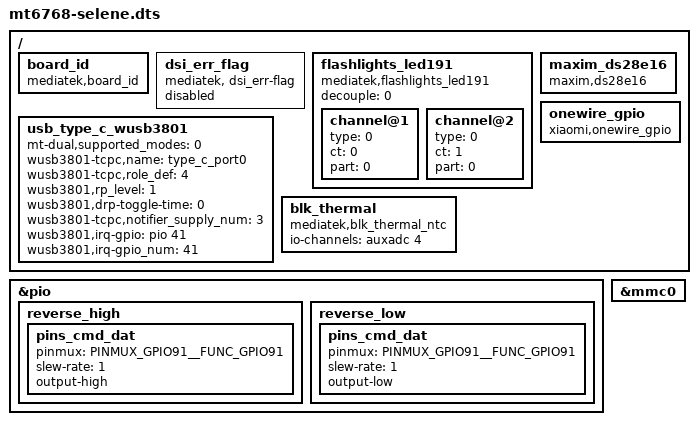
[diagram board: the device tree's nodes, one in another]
// SPDX-License-Identifier: GPL-2.0
/*
 * MT6768 base for selene (Redmi 10): the 4.19 donor base plus the
 * Xiaomi/Huaqin board nodes that selene's overlay references. Node bodies are
 * copied unchanged from the selene 4.14 mt6768.dts.
 */
#include "mt6768.dts"

/ {
    board_id: board_id {
		compatible = "mediatek,board_id";
	};

	dsi_err_flag: dsi_err_flag {
		compatible = "mediatek, dsi_err-flag";
		status = "disabled";
	};

	flashlights_led191: flashlights_led191 {
		compatible = "mediatek,flashlights_led191";
		decouple = <0>;
		channel@1 {
			type = <0>;
			ct = <0>;
			part = <0>;
		};
		channel@2 {
			type = <0>;
			ct = <1>;
			part = <0>;
		};
	};

	maxim_ds28e16: maxim_ds28e16 {
		compatible = "maxim,ds28e16";
	};

	onewire_gpio: onewire_gpio {
		compatible = "xiaomi,onewire_gpio";
	};
};

&pio {
	reverse_high: reverse_high {
		pins_cmd_dat {
			pinmux = <PINMUX_GPIO91__FUNC_GPIO91>;
			slew-rate = <1>;
			output-high;
		};
	};

	reverse_low: reverse_low {
		pins_cmd_dat {
			pinmux = <PINMUX_GPIO91__FUNC_GPIO91>;
			slew-rate = <1>;
			output-low;
		};
	};
};

/*
 * USB-C: the bootloader always applies the signed stock dtbo, whose node for
 * selene's WUSB3801 is i2c5 "usb_type_c@60" (compatible "mediatek,usb_type_c").
 * The 4.19 wusb3801 driver binds that node and reads its settings from a node
 * named "usb_type_c_wusb3801", provided here. IRQ is GPIO41 (selene 4.14
 * type_c_port0 mt6370pd,intr_gpio); no compatible, so no device is created.
 */
/ {
	usb_type_c_wusb3801 {
		mt-dual,supported_modes = <0>;
		wusb3801-tcpc,name = "type_c_port0";
		wusb3801-tcpc,role_def = <4>;
		wusb3801,rp_level = <1>;
		wusb3801,drp-toggle-time = <0>;
		wusb3801-tcpc,notifier_supply_num = <3>;
		wusb3801,irq-gpio = <&pio 41 0x0>;
		wusb3801,irq-gpio_num = <41>;
	};
};

/ {
	/* backlight NTC on AUXADC 4, read by mtk_ts_blk_ntc (selene 4.14) */
	blk_thermal: blk_thermal {
		compatible = "mediatek,blk_thermal_ntc";
		io-channels = <&auxadc 4>;
		io-channel-names = "blk_thermal-channel";
		status = "okay";
	};
};

/*
 * Battery: fire's gauge profile is for its 5000 mAh cells; use selene's
 * (from the selene 4.14 tree) for its 6000 mAh battery.
 */
/delete-node/ &bat_gm30;
/ {
#include "mediatek/bat_setting/selene_battery_prop.dtsi"
};

/*
 * eMMC: no command queue (CQE). On selene's Samsung eMMC, commands issued
 * outside the queue with CQE on (RPMB partition switch, vendor health
 * commands) time out and leave every later command timing out. Stock ran
 * without CQHCI (MTK's own HW CQ stack).
 */
&mmc0 {
	/delete-property/ mediatek,cqhci;
};
